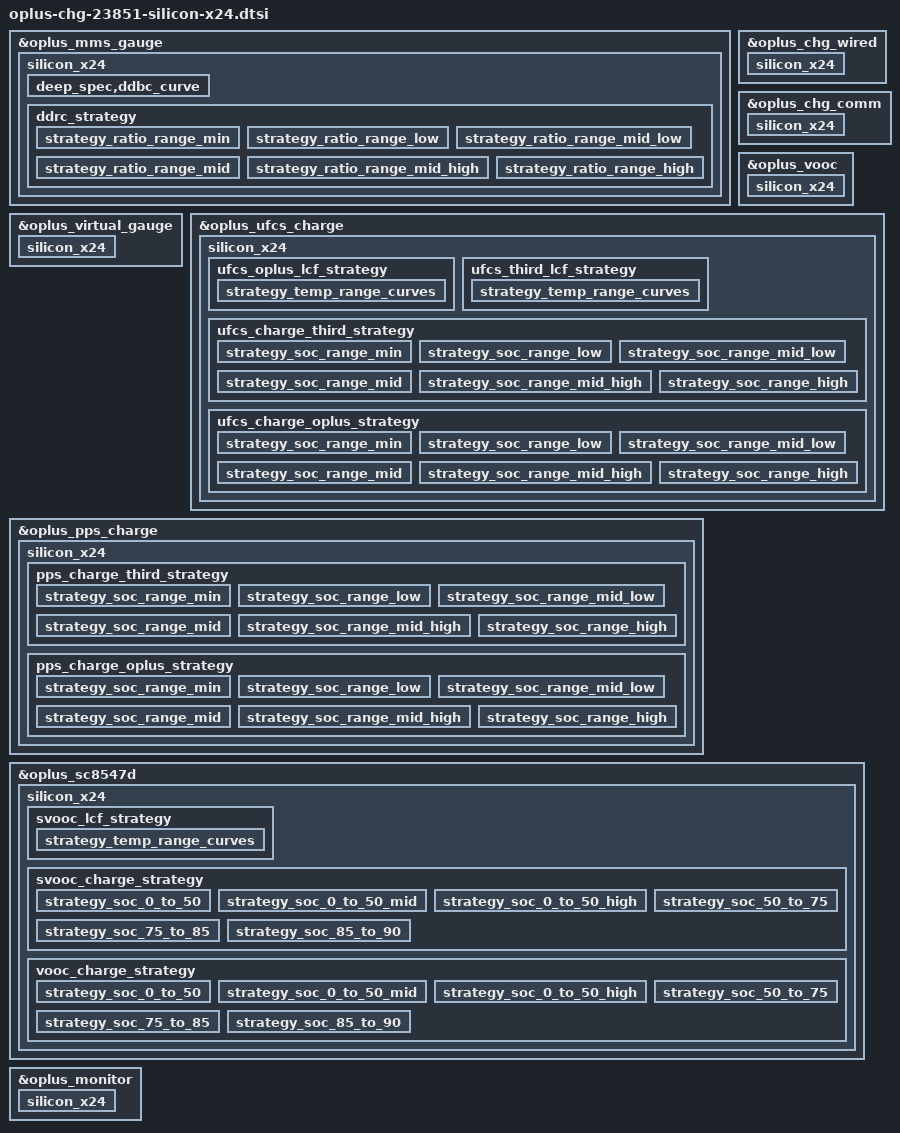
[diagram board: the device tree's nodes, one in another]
&oplus_mms_gauge {
	silicon_x24 {
		oplus,fcl_support;
		oplus,fcl_index = <0>;
		oplus,vb_offset = <30>;
		deep_spec,support;
		deep_spec,uv_thr = <3000>;
		deep_spec,count_thr = <50>;
		deep_spec,vbat_soc = <20>;
		deep_spec,count_step = <0   10 0
					350 12 1
					450 15 2
					530 20 3>;

		deep_spec,term_coeff = <3000 300 0
					3100 450 2
					3200 600 5
					3300 650 7>;
		deep_spec,ddrc_strategy_name = "ddrc_curve";
		deep_spec,volt_step = <20>;
		deep_spec,ddbc_curve {
			oplus,temp_type = <OPLUS_STRATEGY_USE_BATT_TEMP>;
			oplus,temp_range = <(-100) 50 200>;
			deep_spec,ddbc_temp_cold =	<500   3250 5
							 10000 3200 2>;
			deep_spec,ddbc_temp_cool =	<500   3250 5
							 10000 3200 2>;
			deep_spec,ddbc_temp_normal =	<500   3350 5
							 10000 3300 2>;
			deep_spec,ddbc_temp_warm =	<500   3350 5
							 10000 3300 2>;
		};
		ddrc_strategy {
			oplus,temp_type = <OPLUS_STRATEGY_USE_BATT_TEMP>;
			oplus,ratio_range = <20 30 50 70 90>;
			oplus,temp_range = <(-50) 100 350>;
			strategy_ratio_range_min { /* 0 ~ 0.2 */
				strategy_temp_cold =	<0    3000 3000 0
							 15   3000 3000 1
							 1200 3100 3100 2
							 1600 3200 3200 3
							 2000 3300 3300 4>;
				strategy_temp_cool =	<0    3000 3000 0
							 15   3000 3000 1
							 500  3000 3000 2
							 1000 3100 3100 3
							 1500 3200 3200 4
							 2000 3300 3300 5>;
				strategy_temp_normal =	<0    3000 3000 0
							 15   3000 3000 1
							 500  3100 3100 2
							 1000 3200 3200 3
							 1500 3300 3300 4>;
				strategy_temp_warm =	<0    3000 3000 0
							 15   3000 3000 1
							 500  3100 3100 2
							 1000 3200 3200 3
							 1500 3300 3300 4>;
			};
			strategy_ratio_range_low { /* 0.2 ~ 0.3 */
				strategy_temp_cold =	<0    3000 3000 0
							 15   3000 3000 1
							 1000 3100 3100 2
							 1300 3200 3200 3
							 1600 3300 3300 4>;
				strategy_temp_cool =	<0    3000 3000 0
							 15   3000 3000 1
							 400  3000 3000 2
							 800  3100 3100 3
							 1200 3200 3200 4
							 1600 3300 3300 5>;
				strategy_temp_normal =	<0    3000 3000 0
							 15   3000 3000 1
							 400  3100 3100 2
							 800  3200 3200 3
							 1200 3300 3300 4>;
				strategy_temp_warm =	<0    3000 3000 0
							 15   3000 3000 1
							 400  3100 3100 2
							 800  3200 3200 3
							 1200 3300 3300 4>;
			};
			strategy_ratio_range_mid_low { /* 0.3 ~ 0.5 */
				strategy_temp_cold =	<0    3000 3000 0
							 15   3000 3000 1
							 600  3100 3100 2
							 900  3200 3200 3
							 1200 3300 3300 4>;
				strategy_temp_cool =	<0    3000 3000 0
							 15   3000 3000 1
							 300  3000 3000 2
							 600  3100 3100 3
							 900  3200 3200 4
							 1200 3300 3300 5>;
				strategy_temp_normal =	<0    3000 3000 0
							 15   3000 3000 1
							 300  3100 3100 2
							 600  3200 3200 3
							 900  3300 3300 4>;
				strategy_temp_warm =	<0    3000 3000 0
							 15   3000 3000 1
							 300  3100 3100 2
							 600  3200 3200 3
							 900  3300 3300 4>;
			};
			strategy_ratio_range_mid { /* 0.5 ~ 0.7 */
				strategy_temp_cold =	<0    3000 3000 0
							 15   3000 3000 1
							 400  3100 3100 2
							 700  3200 3200 3
							 1000 3300 3300 4>;
				strategy_temp_cool =	<0    3000 3000 0
							 100  3000 3000 1
							 200  3100 3100 2
							 500  3200 3200 3
							 800  3300 3300 4>;
				strategy_temp_normal =	<0    3000 3000 0
							 100  3100 3100 1
							 200  3200 3200 2
							 500  3300 3300 3>;
				strategy_temp_warm =	<0    3000 3000 0
							 100  3100 3100 1
							 200  3200 3200 2
							 500  3300 3300 3>;
			};
			strategy_ratio_range_mid_high { /* 0.7 ~ 0.9 */
				strategy_temp_cold =	<0    3000 3000 0
							 15   3000 3000 1
							 150  3100 3100 2
							 300  3200 3200 3
							 500  3300 3300 4>;
				strategy_temp_cool =	<0    3000 3000 0
							 50   3000 3000 1
							 100  3100 3100 2
							 150  3200 3200 3
							 300  3300 3300 4>;
				strategy_temp_normal =	<0    3000 3000 0
							 50   3100 3100 1
							 100  3200 3200 2
							 150  3300 3300 3>;
				strategy_temp_warm =	<0    3000 3000 0
							 50   3100 3100 1
							 100  3200 3200 2
							 150  3300 3300 3>;
			};
			strategy_ratio_range_high { /* >= 0.9 */
				strategy_temp_cold =	<0    3000 3000 0
							 15   3000 3000 1
							 150  3100 3100 2
							 300  3200 3200 3
							 500  3300 3300 4>;
				strategy_temp_cool =	<0    3000 3000 0
							 50   3000 3000 1
							 100  3100 3100 2
							 150  3200 3200 3
							 300  3300 3300 4>;
				strategy_temp_normal =	<0    3000 3000 0
							 50   3100 3100 1
							 100  3200 3200 2
							 150  3300 3300 3>;
				strategy_temp_warm =	<0    3000 3000 0
							 50   3100 3100 1
							 100  3200 3200 2
							 150  3300 3300 3>;
			};
		};
	};
};

&oplus_virtual_gauge {
	silicon_x24 {
		oplus,gauge_ic = <&oplus_adsp_gauge &oplus_ext_gauge>;
		oplus,gauge_ic_index = <0 1>;
		oplus,gauge_ic_func_group = <&adsp_gauge_groups &bq27541_groups>;
		oplus,batt_capacity_mah = <6415>;
		oplus,ic_type = <OPLUS_CHG_IC_VIRTUAL_GAUGE>;
		oplus,ic_index = <0>;
	};
};

&oplus_chg_wired {
	silicon_x24 {
		oplus,vooc-support;

		oplus_spec,vbatt_pdqc_to_5v_thr = <4500>;
		oplus_spec,vbatt_pdqc_to_9v_thr = <4500>;
		oplus_spec,pd-iclmax-ma = <2000>;
		oplus_spec,qc-iclmax-ma = <2000>;
		oplus_spec,non-standard-ibatmax-ma = <500>;
		oplus_spec,input-power-mw = <
			2500		/* OPLUS_WIRED_CHG_MODE_UNKNOWN */
			2500		/* OPLUS_WIRED_CHG_MODE_SDP */
			7500		/* OPLUS_WIRED_CHG_MODE_CDP */
			10000		/* OPLUS_WIRED_CHG_MODE_DCP */
			10000		/* OPLUS_WIRED_CHG_MODE_VOOC */
			18000		/* OPLUS_WIRED_CHG_MODE_QC */
			18000		/* OPLUS_WIRED_CHG_MODE_PD */
		>;
		oplus_spec,led_on-fccmax-ma = <0 551 2754 4400 4400 4400 4400 1000 0>;
		oplus_spec,fccmax-ma-lv = <
			0 551  2200 2200 2200 2200 2200 2200 0	/* OPLUS_WIRED_CHG_MODE_UNKNOWN */
			0 551  600  600  600  600  600  600  0	/* OPLUS_WIRED_CHG_MODE_SDP */
			0 551  1600 1600 1600 1600 1600 1600 0	/* OPLUS_WIRED_CHG_MODE_CDP */
			0 551  2200 2200 2200 2200 2200 2200 0	/* OPLUS_WIRED_CHG_MODE_DCP */
			0 551  2200 2200 2200 2200 2200 2200 0	/* OPLUS_WIRED_CHG_MODE_VOOC */
			0 551  2754 4400 4400 4400 4400 3366 0	/* OPLUS_WIRED_CHG_MODE_QC */
			0 551  2754 4400 4400 4400 4400 3366 0	/* OPLUS_WIRED_CHG_MODE_PD */
		>;
		oplus_spec,fccmax-ma-hv = <
			0 551  1102 1652 2200 2200 2200 2200 0	/* OPLUS_WIRED_CHG_MODE_UNKNOWN */
			0 551  600  600  600  600  600  600  0	/* OPLUS_WIRED_CHG_MODE_SDP */
			0 551  1102 1600 1600 1600 1600 1600 0	/* OPLUS_WIRED_CHG_MODE_CDP */
			0 551  1102 1652 2200 2200 2200 2200 0	/* OPLUS_WIRED_CHG_MODE_DCP */
			0 551  1102 1652 2200 2200 2200 2200 0	/* OPLUS_WIRED_CHG_MODE_VOOC */
			0 551  1102 1652 2754 4400 4400 3366 0	/* OPLUS_WIRED_CHG_MODE_QC */
			0 551  1102 1652 2754 4400 4400 3366 0	/* OPLUS_WIRED_CHG_MODE_PD */
		>;

		oplus_spec,cool_down_sale_pdqc_vol_mv = <5000>;
		oplus_spec,cool_down_sale_pdqc_curr_ma = <1200>;
		oplus_spec,cool_down_pdqc_vol_mv = <5000 5000 5000 9000 9000>;
		oplus_spec,cool_down_pdqc_curr_ma = <1200 1500 2000 1500 2000>;
		oplus_spec,cool_down_vooc_curr_ma = <1200 1500 2000 2500 3000 3000>;
		oplus_spec,cool_down_normal_curr_ma = <1200 1500 2000>;

		oplus_spec,vbus_ov_thr_mv = <11000 11000>;
		oplus_spec,vbus_uv_thr_mv = <4300 4300>;

		/* first data is strategy used temp type */
		oplus,pd_strategy_name = "cgcl";
		oplus,pd_strategy_data = <OPLUS_STRATEGY_USE_SHELL_TEMP
					    0   420 2000 1 0
					    410 430 1500 2 0
					    420 440 1200 2 1>;
		oplus,qc_strategy_name = "cgcl";
		oplus,qc_strategy_data = <OPLUS_STRATEGY_USE_SHELL_TEMP
					    0   420 2000 1 0
					    410 430 1500 2 0
					    420 440 1200 2 1>;
	};
};

&oplus_chg_comm {
	silicon_x24 {
		oplus_spec,dec_step = <20>;
		oplus_spec,dec-vol-cc-full-thr = <0 400 600 800 1000 1200>;
		oplus_spec,dec-vol-fv-full-mv = <0 20 20 40 40 40>;
		oplus_spec,batt-them-thr = <(-100) 0 50 120 160 350 450 530>;
		oplus_spec,iterm-ma = <316>;
		oplus_spec,removed_bat_decidegc = <390>;
		oplus_spec,fv-mv = <4500 4500 4500 4500 4500 4500 4475 4130 4130>;
		oplus_spec,sw-fv-mv = <4450 4450 4450 4450 4450 4450 4425 4080 4080>;
		oplus_spec,hw-fv-inc-mv = <0 18 18 18 18 18 18 18 0>;
		oplus_spec,sw-over-fv-mv = <4505 4505 4505 4505 4505 4505 4480 4135 4135>;
		oplus_spec,sw-over-fv-dec-mv = <10>;
		oplus_spec,non-standard-sw-fv-mv = <3930>;
		oplus_spec,non-standard-fv-mv = <3980>;
		oplus_spec,non-standard-hw-fv-inc-mv = <18>;
		oplus_spec,non-standard-sw-over-fv-mv = <3985>;
		oplus_spec,non-standard-vbatdet-mv = <3680>;
		oplus_spec,wired-vbatdet-mv = <0 4200 4300 4400 4400 4400 4375 4030 0>;
		oplus_spec,fcc-gear-thr-mv = <4180>;
		oplus_spec,fcc-gear-shake-mv = <500 500 500 400 300 200 200 200 200>;
		oplus_spec,vbatt-ov-thr-mv = <4600>;

		oplus_spec,full_pre_ffc_judge;
		oplus_spec,full-pre-ffc-mv = <4495>;
		oplus_spec,ffc-temp-thr = <120 210 350 440>;
		oplus_spec,wired-ffc-step-max = <2>;
		oplus_spec,wired-ffc-fv-mv = <4630 4630>;

		oplus_spec,wired-ffc-fv-cutoff-mv = <4545 4545 4545
						     4545 4545 4545>;
		oplus_spec,wired-ffc-fcc-ma = <1500 1500 2050
					       1000 1300 1950>;
		oplus_spec,wired-ffc-fcc-cutoff-ma = <1300 1300 1850
						      900  1200 1850>;

		oplus_spec,vbat_uv_thr_mv = <3000>;
		oplus_spec,vbat_charging_uv_thr_mv = <2900>;

		/*If use subboard NTC as battery temp, config it as 20, otherwise 0 */
		oplus_spec,tbatt_power_off_cali_temp = <0>;
		oplus_spec,poweroff_high_batt_temp = <720>;
		oplus_spec,poweroff_emergency_batt_temp = <770>;
		oplus,vooc_show_ui_soc_decimal;
		oplus,ui_soc_decimal_speedmin = <20>;

		oplus,gauge_stuck_jump_support;
		oplus,gauge_stuck_threshold = <15>;
		oplus,gauge_stuck_time = <50>;

		oplus,smooth_switch;
		oplus,reserve_chg_soc = <2>;

		oplus,ui_soc_2_voltage_comp_mv = <30>;
		oplus,chg_shutdown_max_mv = <3000>;

		oplus_spec,drop_soc_2_temp_ladder = <(-50) 0 0 0 0 0 0 0 0 0>;
		oplus_spec,volt_diff_ladder_of_drop_soc_2 = <80 80 0 0 0 0 0 0 0 0>;
		oplus_spec,keep_soc_2_temp_ladder = <(-200) (-50) 0 0 0 0 0 0 0 0>;
		oplus_spec,volt_diff_ladder_of_keep_soc_2 = <10 20 30 0 0 0 0 0 0 0>;
		oplus_spec,back_rm_of_drop_soc_2 = <32>;
		oplus_spec,back_rm_of_drop_soc_1 = <0>;
		oplus_spec,load_current_of_drop_soc_2 = <1000>;
		oplus_spec,load_current_of_drop_soc_1 = <2000>;
		oplus_spec,current_limit_of_drop_soc_2 = <700>;
		oplus_spec,volt_of_fast_drop_soc_1 = <2900>;
		oplus_spec,support_uisoc_low_battery_control;

		oplus_spec,batt_full_time = <300>;
	};
};

&oplus_vooc {
	silicon_x24 {
		oplus,vooc_ic = <&oplus_virtual_vphy>;

		oplus_spec,vooc_soc_range = <50 75 85>;

		oplus,vooc_data_width = <7>;
		oplus,vooc_curr_max = <CP_CURR_LIMIT_7BIT_15_0A>;
		oplus,vooc_project = <VOOC_PROJECT_10V8A_TWO_BAT_SVOOC>;
		oplus,vooc_curr_table_type = <VOOC_CP_CURR_TABLE>;
		oplus,vooc_power_max_w = <80>;
		oplus,voocphy_support = <AP_DUAL_CP_VOOCPHY>;
		oplus,support_fake_vooc_check;
		oplus,smart_chg_bcc_support;
		oplus,subboard_ntc_abnormal_current = <4000>;

		oplus,abnormal_adapter_current = <CP_CURR_LIMIT_7BIT_15_0A CP_CURR_LIMIT_7BIT_15_0A
						CP_CURR_LIMIT_7BIT_10_0A CP_CURR_LIMIT_7BIT_10_0A
						CP_CURR_LIMIT_7BIT_8_0A CP_CURR_LIMIT_7BIT_8_0A
						CP_CURR_LIMIT_7BIT_6_0A CP_CURR_LIMIT_7BIT_6_0A
						CP_CURR_LIMIT_7BIT_4_0A CP_CURR_LIMIT_7BIT_4_0A>;

		oplus,abnormal_over_80w_adapter_current = <CP_CURR_LIMIT_7BIT_15_0A CP_CURR_LIMIT_7BIT_15_0A
						CP_CURR_LIMIT_7BIT_14_0A CP_CURR_LIMIT_7BIT_14_0A
						CP_CURR_LIMIT_7BIT_12_0A CP_CURR_LIMIT_7BIT_12_0A
						CP_CURR_LIMIT_7BIT_10_0A CP_CURR_LIMIT_7BIT_10_0A
						CP_CURR_LIMIT_7BIT_8_0A  CP_CURR_LIMIT_7BIT_8_0A
						CP_CURR_LIMIT_7BIT_6_0A  CP_CURR_LIMIT_7BIT_6_0A
						CP_CURR_LIMIT_7BIT_4_0A CP_CURR_LIMIT_7BIT_4_0A>;

		/* first data is strategy used temp type */
		oplus,general_strategy_name = "cgcl";
		oplus,general_strategy_data = <OPLUS_STRATEGY_USE_SHELL_TEMP
						0   385 CP_CURR_LIMIT_7BIT_15_0A 1 0
						375 405 CP_CURR_LIMIT_7BIT_10_0A 2 0
						395 420 CP_CURR_LIMIT_7BIT_8_0A  3 1
						410 430 CP_CURR_LIMIT_7BIT_7_0A  4 2
						420 440 CP_CURR_LIMIT_7BIT_4_0A  4 3>;

		oplus,bypass_strategy_name = "cgcl";
		oplus,bypass_strategy_data = <OPLUS_STRATEGY_USE_SHELL_TEMP
						0   395 CP_CURR_LIMIT_7BIT_6_0A  1 0
						385 405 CP_CURR_LIMIT_7BIT_4_0A  2 0
						395 415 CP_CURR_LIMIT_7BIT_3_0A  3 1
						405 440 CP_CURR_LIMIT_7BIT_2_0A  3 2>;

		oplus,plc_strategy-data = <&buck_simple_strategy &cp_2t1_simple_strategy &cp_1t1_simple_strategy>;
		oplus,plc_strategy-names = "default", "svooc", "vooc";
	};
};

&oplus_ufcs_charge {
	silicon_x24 {
		oplus,ufcs_ic = <&oplus_virtual_ufcs>;
		oplus,cp_ic = <&oplus_virtual_cp>;
		oplus,dpdm_switch_ic = <&oplus_virtual_dpdm_switch>;

		oplus,impedance_unit = <&oplus_ufcs_impedance_unit>;

		oplus,target_vbus_mv = <11000>;
		oplus,curr_max_ma = <3000>;
		oplus,curr_table_type = <UFCS_CURR_CP_TABLE>;
		oplus,high_imp_compensation_setting_mv = <50>;
		oplus,subboard_ntc_abnormal_current = <4000>;
		oplus,lift_vbus_use_cpvout;

		oplus,ufcs_warm_allow_vol = <4000>;
		oplus,ufcs_warm_allow_soc = <55>;
		oplus,ufcs_strategy_normal_current = <3000>;
		oplus,ufcs_over_high_or_low_current = <3000>;
		oplus,ufcs_timeout_third = <15737>;
		oplus,ufcs_timeout_oplus = <15737>;
		oplus,ufcs_ibat_over_third = <7400>;
		oplus,ufcs_ibat_over_oplus = <7400>;
		oplus,ufcs_full_cool_sw_vbat = <4550>;
		oplus,ufcs_full_normal_sw_vbat = <4550>;
		oplus,ufcs_full_normal_hw_vbat = <4560>;
		oplus,ufcs_full_warm_vbat = <4130>;
		oplus,ufcs_full_cool_sw_vbat_third = <4500>;
		oplus,ufcs_full_normal_sw_vbat_third= <4500>;
		oplus,ufcs_full_normal_hw_vbat_third = <4510>;
		oplus,ufcs_strategy_batt_high_temp = <405 420 430 395 410 425>;
		oplus,ufcs_strategy_high_current = <3000 2500 2000 3000 3000 2500>;
		oplus,ufcs_little_cool_high_temp = <210>;
		oplus,curve_strategy_name = "pps_ufcs_curve_v2";
		oplus,ufcs_charge_strategy_soc = <0 20 35 55 75 85 95>;
		oplus,ufcs_charge_strategy_temp = <0 50 120 160 350 440 510>;
		oplus_spec,ufcs_low_temp = <0>;
		oplus_spec,ufcs_high_temp = <500>;
		oplus_spec,ufcs_low_soc = <0>;
		oplus_spec,ufcs_high_soc = <95>;

		oplus,plc_strategy-data = <&oplus_ufcs_step_strategy &cp_2t1_simple_strategy>;
		oplus,plc_strategy-names = "default", "third";

		ufcs_oplus_lcf_strategy {
			oplus,temp_type = <OPLUS_STRATEGY_USE_SHELL_TEMP>;
			oplus,temp_range = <0 50 120 160 210 380 440>;

			strategy_temp_range_curves {
				strategy_temp_range_t0 =	<700  4550 0
								 675  4540 0
								 650  4530 0
								 625  4520 0
								 600  4510 1>;
				strategy_temp_range_t1 =	<780  4550 0
								 745  4545 0
								 710  4530 0
								 675  4520 0
								 640  4510 1>;
				strategy_temp_range_t2 =	<800  4550 0
								 755  4545 0
								 710  4530 0
								 665  4520 0
								 620  4510 1>;
				strategy_temp_range_t3 =	<950  4550 0
								 900  4545 0
								 800  4530 0
								 700  4520 0
								 550  4510 1>;
				strategy_temp_range_t4 =	<1250 4550 0
								 1200 4545 0
								 1100 4530 0
								 1000 4520 0
								 850  4510 1>;
				strategy_temp_range_t5 =	<1900 4550 0
								 1850 4545 0
								 1750 4530 0
								 1650 4520 0
								 1500 4510 1>;
			};
		};

		ufcs_third_lcf_strategy {
			oplus,temp_type = <OPLUS_STRATEGY_USE_SHELL_TEMP>;
			oplus,temp_range = <0 50 120 160 210 380 440>;

			strategy_temp_range_curves {
				strategy_temp_range_t0 =	<700  4550 0
								 675  4540 0
								 650  4530 0
								 625  4520 0
								 600  4510 1>;
				strategy_temp_range_t1 =	<780  4550 0
								 745  4545 0
								 710  4530 0
								 675  4520 0
								 640  4510 1>;
				strategy_temp_range_t2 =	<800  4550 0
								 755  4545 0
								 710  4530 0
								 665  4520 0
								 620  4510 1>;
				strategy_temp_range_t3 =	<950  4550 0
								 900  4545 0
								 800  4530 0
								 700  4520 0
								 550  4510 1>;
				strategy_temp_range_t4 =	<1250 4550 0
								 1200 4545 0
								 1100 4530 0
								 1000 4520 0
								 850  4510 1>;
				strategy_temp_range_t5 =	<1900 4550 0
								 1850 4545 0
								 1750 4530 0
								 1650 4520 0
								 1500 4510 1>;
			};
		};

		ufcs_charge_third_strategy {
			oplus,temp_type = <OPLUS_STRATEGY_USE_SHELL_TEMP>;
			oplus,soc_range = <0 20 35 55 75 85 95>;
			oplus,temp_range = <0 50 120 160 210 350 440 510>;

			strategy_soc_range_min { /* 0 ~ 20 */
				strategy_temp_little_cold =	<11000 4140 1450 0 0
								 11000 4150 1000 1 0>;
				strategy_temp_cool =		<11000 4150 2350 0 0
								 11000 4150 2000 0 0
								 11000 4150 1500 0 0
								 11000 4490 1450 0 0
								 11000 4500 1000 1 0>;
				strategy_temp_little_cool =	<11000 4150 2900 0 0
								 11000 4150 2500 0 0
								 11000 4260 2350 0 0
								 11000 4260 2000 0 0
								 11000 4260 1500 0 0
								 11000 4490 1450 0 0
								 11000 4500 1000 1 0>;
				strategy_temp_little_cool_high =<11000 4490 3000 0 0
								 11000 4490 2900 0 0
								 11000 4490 2500 0 0
								 11000 4490 2000 0 0
								 11000 4490 1500 0 0
								 11000 4500 1000 1 0>;
				strategy_temp_normal_low =	<11000 4480 3000 0 0
								 11000 4490 2750 0 0
								 11000 4490 2500 0 0
								 11000 4490 2000 0 0
								 11000 4490 1500 0 0
								 11000 4500 1000 1 0>;
				strategy_temp_normal_high =	<11000 4465 3000 0 0
								 11000 4465 2750 0 0
								 11000 4465 2500 0 0
								 11000 4465 2000 0 0
								 11000 4465 1500 0 0
								 11000 4475 1000 1 0>;
				strategy_temp_warm =		<11000 4120 1650 0 0
								 11000 4120 1500 0 0
								 11000 4130 1000 1 0>;
			};
			strategy_soc_range_low { /* 21 ~ 35 */
				strategy_temp_little_cold =	<11000 4140 1450 0 0
								 11000 4150 1000 1 0>;
				strategy_temp_cool =		<11000 4150 2350 0 0
								 11000 4150 2000 0 0
								 11000 4150 1500 0 0
								 11000 4490 1450 0 0
								 11000 4500 1000 1 0>;
				strategy_temp_little_cool =	<11000 4150 2900 0 0
								 11000 4150 2500 0 0
								 11000 4260 2350 0 0
								 11000 4260 2000 0 0
								 11000 4260 1500 0 0
								 11000 4490 1450 0 0
								 11000 4500 1000 1 0>;
				strategy_temp_little_cool_high =<11000 4490 3000 0 0
								 11000 4490 2900 0 0
								 11000 4490 2500 0 0
								 11000 4490 2000 0 0
								 11000 4490 1500 0 0
								 11000 4500 1000 1 0>;
				strategy_temp_normal_low =	<11000 4480 3000 0 0
								 11000 4490 2750 0 0
								 11000 4490 2500 0 0
								 11000 4490 2000 0 0
								 11000 4490 1500 0 0
								 11000 4500 1000 1 0>;
				strategy_temp_normal_high =	<11000 4465 3000 0 0
								 11000 4465 2750 0 0
								 11000 4465 2500 0 0
								 11000 4465 2000 0 0
								 11000 4465 1500 0 0
								 11000 4475 1000 1 0>;
				strategy_temp_warm =		<11000 4120 1650 0 0
								 11000 4120 1500 0 0
								 11000 4130 1000 1 0>;
			};
			strategy_soc_range_mid_low { /* 36 ~ 55 */
				strategy_temp_little_cold =	<11000 4140 1450 0 0
								 11000 4150 1000 1 0>;
				strategy_temp_cool =		<11000 4150 2350 0 0
								 11000 4150 2000 0 0
								 11000 4150 1500 0 0
								 11000 4490 1450 0 0
								 11000 4500 1000 1 0>;
				strategy_temp_little_cool =	<11000 4150 2900 0 0
								 11000 4150 2500 0 0
								 11000 4260 2350 0 0
								 11000 4260 2000 0 0
								 11000 4260 1500 0 0
								 11000 4490 1450 0 0
								 11000 4500 1000 1 0>;
				strategy_temp_little_cool_high =<11000 4490 3000 0 0
								 11000 4490 2900 0 0
								 11000 4490 2500 0 0
								 11000 4490 2000 0 0
								 11000 4490 1500 0 0
								 11000 4500 1000 1 0>;
				strategy_temp_normal_low =	<11000 4480 3000 0 0
								 11000 4490 2750 0 0
								 11000 4490 2500 0 0
								 11000 4490 2000 0 0
								 11000 4490 1500 0 0
								 11000 4500 1000 1 0>;
				strategy_temp_normal_high =	<11000 4465 3000 0 0
								 11000 4465 2750 0 0
								 11000 4465 2500 0 0
								 11000 4465 2000 0 0
								 11000 4465 1500 0 0
								 11000 4475 1000 1 0>;
				strategy_temp_warm =		<11000 4120 1650 0 0
								 11000 4120 1500 0 0
								 11000 4130 1000 1 0>;
			};
			strategy_soc_range_mid { /* 56 ~ 75*/
				strategy_temp_little_cold =	<11000 4140 1450 0 0
								 11000 4150 1000 1 0>;
				strategy_temp_cool =		<11000 4150 1500 0 0
								 11000 4490 1450 0 0
								 11000 4500 1000 1 0>;
				strategy_temp_little_cool =	<11000 4260 2000 0 0
								 11000 4260 1500 0 0
								 11000 4490 1450 0 0
								 11000 4500 1000 1 0>;
				strategy_temp_little_cool_high =<11000 4490 2000 0 0
								 11000 4490 1500 0 0
								 11000 4500 1000 1 0>;
				strategy_temp_normal_low =	<11000 4490 2000 0 0
								 11000 4490 1500 0 0
								 11000 4500 1000 1 0>;
				strategy_temp_normal_high =	<11000 4465 2500 0 0
								 11000 4465 2000 0 0
								 11000 4465 1500 0 0
								 11000 4475 1000 1 0>;
				strategy_temp_warm =		<11000 4120 1650 0 0
								 11000 4120 1500 0 0
								 11000 4130 1000 1 0>;
			};
			strategy_soc_range_mid_high { /* 76 ~ 85 */
				strategy_temp_little_cold =	<11000 4150 1000 1 0>;
				strategy_temp_cool =		<11000 4500 1000 1 0>;
				strategy_temp_little_cool =	<11000 4260 1500 0 0
								 11000 4490 1450 0 0
								 11000 4500 1000 1 0>;
				strategy_temp_little_cool_high =<11000 4490 1500 0 0
								 11000 4500 1000 1 0>;
				strategy_temp_normal_low =	<11000 4490 1500 0 0
								 11000 4500 1000 1 0>;
				strategy_temp_normal_high =	<11000 4465 1500 0 0
								 11000 4475 1000 1 0>;
				strategy_temp_warm =		<11000 4120 1650 0 0
								 11000 4120 1500 0 0
								 11000 4130 1000 1 0>;
			};
			strategy_soc_range_high { /* 86 ~ 95 */
				strategy_temp_little_cold =	<11000 4150 1000 1 0>;
				strategy_temp_cool =		<11000 4500 1000 1 0>;
				strategy_temp_little_cool =	<11000 4500 1000 1 0>;
				strategy_temp_little_cool_high =<11000 4500 1000 1 0>;
				strategy_temp_normal_low =	<11000 4500 1000 1 0>;
				strategy_temp_normal_high =	<11000 4475 1000 1 0>;
				strategy_temp_warm =		<11000 4120 1650 0 0
								 11000 4120 1500 0 0
								 11000 4130 1000 1 0>;
			};
		};

		ufcs_charge_oplus_strategy {
			oplus,temp_type = <OPLUS_STRATEGY_USE_SHELL_TEMP>;
			oplus,soc_range = <0 20 35 55 75 85 95>;
			oplus,temp_range = <0 50 120 160 210 350 440 510>;

			strategy_soc_range_min { /* 0 ~ 20 */
				strategy_temp_little_cold =	<11000 4140 1450 0 0
								 11000 4150 1000 1 0>;
				strategy_temp_cool =		<11000 4150 2350 0 0
								 11000 4150 2000 0 0
								 11000 4150 1500 0 0
								 11000 4500 1450 0 0
								 11000 4510 1000 1 0>;
				strategy_temp_little_cool =	<11000 4150 2900 0 0
								 11000 4150 2500 0 0
								 11000 4260 2350 0 0
								 11000 4260 2000 0 0
								 11000 4260 1500 0 0
								 11000 4540 1450 0 0
								 11000 4550 1000 1 0>;
				strategy_temp_little_cool_high =<11000 4500 3000 0 0
								 11000 4540 2900 0 0
								 11000 4540 2500 0 0
								 11000 4540 2000 0 0
								 11000 4540 1500 0 0
								 11000 4550 1000 1 0>;
				strategy_temp_normal_low =	<11000 4480 3000 0 0
								 11000 4540 2750 0 0
								 11000 4540 2500 0 0
								 11000 4540 2000 0 0
								 11000 4540 1500 0 0
								 11000 4550 1000 1 0>;
				strategy_temp_normal_high =	<11000 4480 3000 0 0
								 11000 4540 2750 0 0
								 11000 4540 2500 0 0
								 11000 4540 2000 0 0
								 11000 4540 1500 0 0
								 11000 4550 1000 1 0>;
				strategy_temp_warm =		<11000 4120 1650 0 0
								 11000 4120 1500 0 0
								 11000 4130 1000 1 0>;
			};
			strategy_soc_range_low { /* 21 ~ 35 */
				strategy_temp_little_cold =	<11000 4140 1450 0 0
								 11000 4150 1000 1 0>;
				strategy_temp_cool =		<11000 4150 2350 0 0
								 11000 4150 2000 0 0
								 11000 4150 1500 0 0
								 11000 4500 1450 0 0
								 11000 4510 1000 1 0>;
				strategy_temp_little_cool =	<11000 4150 2900 0 0
								 11000 4150 2500 0 0
								 11000 4260 2350 0 0
								 11000 4260 2000 0 0
								 11000 4260 1500 0 0
								 11000 4540 1450 0 0
								 11000 4550 1000 1 0>;
				strategy_temp_little_cool_high =<11000 4500 3000 0 0
								 11000 4540 2900 0 0
								 11000 4540 2500 0 0
								 11000 4540 2000 0 0
								 11000 4540 1500 0 0
								 11000 4550 1000 1 0>;
				strategy_temp_normal_low =	<11000 4480 3000 0 0
								 11000 4540 2750 0 0
								 11000 4540 2500 0 0
								 11000 4540 2000 0 0
								 11000 4540 1500 0 0
								 11000 4550 1000 1 0>;
				strategy_temp_normal_high =	<11000 4480 3000 0 0
								 11000 4540 2750 0 0
								 11000 4540 2500 0 0
								 11000 4540 2000 0 0
								 11000 4540 1500 0 0
								 11000 4550 1000 1 0>;
				strategy_temp_warm =		<11000 4120 1650 0 0
								 11000 4120 1500 0 0
								 11000 4130 1000 1 0>;
			};
			strategy_soc_range_mid_low { /* 36 ~ 55 */
				strategy_temp_little_cold =	<11000 4140 1450 0 0
								 11000 4150 1000 1 0>;
				strategy_temp_cool =		<11000 4150 2350 0 0
								 11000 4150 2000 0 0
								 11000 4150 1500 0 0
								 11000 4500 1450 0 0
								 11000 4510 1000 1 0>;
				strategy_temp_little_cool =	<11000 4150 2900 0 0
								 11000 4150 2500 0 0
								 11000 4260 2350 0 0
								 11000 4260 2000 0 0
								 11000 4260 1500 0 0
								 11000 4540 1450 0 0
								 11000 4550 1000 1 0>;
				strategy_temp_little_cool_high =<11000 4500 3000 0 0
								 11000 4540 2900 0 0
								 11000 4540 2500 0 0
								 11000 4540 2000 0 0
								 11000 4540 1500 0 0
								 11000 4550 1000 1 0>;
				strategy_temp_normal_low =	<11000 4480 3000 0 0
								 11000 4540 2750 0 0
								 11000 4540 2500 0 0
								 11000 4540 2000 0 0
								 11000 4540 1500 0 0
								 11000 4550 1000 1 0>;
				strategy_temp_normal_high =	<11000 4480 3000 0 0
								 11000 4540 2750 0 0
								 11000 4540 2500 0 0
								 11000 4540 2000 0 0
								 11000 4540 1500 0 0
								 11000 4550 1000 1 0>;
				strategy_temp_warm =		<11000 4120 1650 0 0
								 11000 4120 1500 0 0
								 11000 4130 1000 1 0>;
			};
			strategy_soc_range_mid { /* 56 ~ 75 */
				strategy_temp_little_cold =	<11000 4140 1450 0 0
								 11000 4150 1000 1 0>;
				strategy_temp_cool =		<11000 4150 1500 0 0
								 11000 4500 1450 0 0
								 11000 4510 1000 1 0>;
				strategy_temp_little_cool =	<11000 4260 2000 0 0
								 11000 4260 1500 0 0
								 11000 4540 1450 0 0
								 11000 4550 1000 1 0>;
				strategy_temp_little_cool_high =<11000 4540 2000 0 0
								 11000 4540 1500 0 0
								 11000 4550 1000 1 0>;
				strategy_temp_normal_low =	<11000 4540 2500 0 0
								 11000 4540 2000 0 0
								 11000 4540 1500 0 0
								 11000 4550 1000 1 0>;
				strategy_temp_normal_high =	<11000 4480 3000 0 0
								 11000 4540 2750 0 0
								 11000 4540 2500 0 0
								 11000 4540 2000 0 0
								 11000 4540 1500 0 0
								 11000 4550 1000 1 0>;
				strategy_temp_warm =		<11000 4120 1650 0 0
								 11000 4120 1500 0 0
								 11000 4130 1000 1 0>;
			};
			strategy_soc_range_mid_high { /* 76 ~ 85 */
				strategy_temp_little_cold =	<11000 4150 1000 1 0>;
				strategy_temp_cool =		<11000 4510 1000 1 0>;
				strategy_temp_little_cool =	<11000 4260 1500 0 0
								 11000 4540 1450 0 0
								 11000 4550 1000 1 0>;
				strategy_temp_little_cool_high =<11000 4540 1500 0 0
								 11000 4550 1000 1 0>;
				strategy_temp_normal_low =	<11000 4540 1500 0 0
								 11000 4550 1000 1 0>;
				strategy_temp_normal_high =	<11000 4540 2000 0 0
								 11000 4540 1500 0 0
								 11000 4550 1000 1 0>;
				strategy_temp_warm =		<11000 4120 1650 0 0
								 11000 4120 1500 0 0
								 11000 4130 1000 1 0>;
			};
			strategy_soc_range_high { /* 86 ~ 95 */
				strategy_temp_little_cold =	<11000 4150 1000 1 0>;
				strategy_temp_cool =		<11000 4510 1000 1 0>;
				strategy_temp_little_cool =	<11000 4550 1000 1 0>;
				strategy_temp_little_cool_high =<11000 4550 1000 1 0>;
				strategy_temp_normal_low =	<11000 4550 1000 1 0>;
				strategy_temp_normal_high =	<11000 4550 1000 1 0>;
				strategy_temp_warm =		<11000 4120 1650 0 0
								 11000 4120 1500 0 0
								 11000 4130 1000 1 0>;
			};
		};
	};
};

&oplus_pps_charge {
	silicon_x24 {
		oplus,pps_ic = <&oplus_virtual_pps>;
		oplus,cp_ic = <&oplus_virtual_cp>;
		oplus,dpdm_switch_ic = <&oplus_virtual_dpdm_switch>;

		oplus,target_vbus_mv = <11000>;
		oplus,curr_max_ma = <5000>;
		oplus,lift_vbus_use_cpvout;
		oplus,process_close_cp_item;

		oplus,pps_warm_allow_vol = <4000>;
		oplus,pps_warm_allow_soc = <55>;
		oplus,pps_strategy_normal_current = <5000>;
		oplus,pps_over_high_or_low_current = <5000>;
		oplus,pps_timeout_third = <15737>;
		oplus,pps_timeout_oplus = <15737>;
		oplus,pps_ibat_over_third = <55 11400
					     33 7400>;
		oplus,pps_ibat_over_oplus = <55 11400
					     33 7400>;
		oplus,pps_full_cool_sw_vbat = <4500>;
		oplus,pps_full_normal_sw_vbat = <4500>;
		oplus,pps_full_normal_hw_vbat = <4510>;
		oplus,pps_full_warm_vbat = <4130>;
		oplus,pps_full_cool_sw_vbat_third = <4500>;
		oplus,pps_full_normal_sw_vbat_third= <4500>;
		oplus,pps_full_normal_hw_vbat_third = <4510>;
		oplus,pps_strategy_batt_high_temp = <410 430 435 400 425 430>;
		oplus,pps_strategy_high_current = <5000 3000 2000 5000 5000 3000>;
		oplus,pps_little_cool_high_temp = <210>;
		oplus,curve_strategy_name = "pps_ufcs_curve_v2";
		oplus,pps_charge_strategy_soc = <0 20 35 55 75 85 95>;
		oplus,pps_charge_strategy_temp = <0 50 120 160 350 440 510>;

		oplus,plc_strategy-data = <&cp_2t1_simple_strategy>;
		oplus,plc_strategy-names = "default";

		pps_charge_third_strategy {
			oplus,temp_type = <OPLUS_STRATEGY_USE_SHELL_TEMP>;
			oplus,soc_range = <0 20 35 55 75 85 95>;
			oplus,temp_range = <0 50 120 160 210 350 440 510>;

			strategy_soc_range_min { /* 0 ~ 20 */
				strategy_temp_little_cold =	<11000 4140 1450 0 0
								 11000 4150 1000 1 0>;
				strategy_temp_cool =		<11000 4150 2350 0 0
								 11000 4150 2000 0 0
								 11000 4150 1500 0 0
								 11000 4490 1450 0 0
								 11000 4500 1000 1 0>;
				strategy_temp_little_cool =	<11000 4150 2900 0 0
								 11000 4150 2500 0 0
								 11000 4260 2350 0 0
								 11000 4260 2000 0 0
								 11000 4260 1500 0 0
								 11000 4490 1450 0 0
								 11000 4500 1000 1 0>;
				strategy_temp_little_cool_high =<11000 4170 5000 0 600
								 11000 4170 4500 0 0
								 11000 4260 4350 0 0
								 11000 4260 4000 0 0
								 11000 4490 3500 0 0
								 11000 4490 3000 0 0
								 11000 4490 2900 0 0
								 11000 4490 2500 0 0
								 11000 4490 2000 0 0
								 11000 4490 1500 0 0
								 11000 4500 1000 1 0>;
				strategy_temp_normal_low =	<11000 4190 5000 0 600
								 11000 4250 4950 0 0
								 11000 4250 4000 0 0
								 11000 4410 3850 0 0
								 11000 4480 3550 0 0
								 11000 4480 3500 0 0
								 11000 4480 3000 0 0
								 11000 4490 2750 0 0
								 11000 4490 2500 0 0
								 11000 4490 2000 0 0
								 11000 4490 1500 0 0
								 11000 4500 1000 1 0>;
				strategy_temp_normal_high =	<11000 4190 5000 0 600
								 11000 4250 4950 0 0
								 11000 4250 4000 0 0
								 11000 4410 3850 0 0
								 11000 4465 3550 0 0
								 11000 4465 3500 0 0
								 11000 4465 3000 0 0
								 11000 4465 2750 0 0
								 11000 4465 2500 0 0
								 11000 4465 2000 0 0
								 11000 4465 1500 0 0
								 11000 4475 1000 1 0>;
				strategy_temp_warm =		<11000 4120 1650 0 0
								 11000 4120 1500 0 0
								 11000 4130 1000 1 0>;
			};
			strategy_soc_range_low { /* 21 ~ 35 */
				strategy_temp_little_cold =	<11000 4140 1450 0 0
								 11000 4150 1000 1 0>;
				strategy_temp_cool =		<11000 4150 2350 0 0
								 11000 4150 2000 0 0
								 11000 4150 1500 0 0
								 11000 4490 1450 0 0
								 11000 4500 1000 1 0>;
				strategy_temp_little_cool =	<11000 4150 2900 0 0
								 11000 4150 2500 0 0
								 11000 4260 2350 0 0
								 11000 4260 2000 0 0
								 11000 4260 1500 0 0
								 11000 4490 1450 0 0
								 11000 4500 1000 1 0>;
				strategy_temp_little_cool_high =<11000 4170 5000 0 600
								 11000 4170 4500 0 0
								 11000 4260 4350 0 0
								 11000 4260 4000 0 0
								 11000 4490 3500 0 0
								 11000 4490 3000 0 0
								 11000 4490 2900 0 0
								 11000 4490 2500 0 0
								 11000 4490 2000 0 0
								 11000 4490 1500 0 0
								 11000 4500 1000 1 0>;
				strategy_temp_normal_low =	<11000 4190 5000 0 600
								 11000 4250 4950 0 0
								 11000 4250 4000 0 0
								 11000 4410 3850 0 0
								 11000 4480 3550 0 0
								 11000 4480 3500 0 0
								 11000 4480 3000 0 0
								 11000 4490 2750 0 0
								 11000 4490 2500 0 0
								 11000 4490 2000 0 0
								 11000 4490 1500 0 0
								 11000 4500 1000 1 0>;
				strategy_temp_normal_high =	<11000 4190 5000 0 600
								 11000 4250 4950 0 0
								 11000 4250 4000 0 0
								 11000 4410 3850 0 0
								 11000 4465 3550 0 0
								 11000 4465 3500 0 0
								 11000 4465 3000 0 0
								 11000 4465 2750 0 0
								 11000 4465 2500 0 0
								 11000 4465 2000 0 0
								 11000 4465 1500 0 0
								 11000 4475 1000 1 0>;
				strategy_temp_warm =		<11000 4120 1650 0 0
								 11000 4120 1500 0 0
								 11000 4130 1000 1 0>;
			};
			strategy_soc_range_mid_low { /* 36 ~ 55 */
				strategy_temp_little_cold =	<11000 4140 1450 0 0
								 11000 4150 1000 1 0>;
				strategy_temp_cool =		<11000 4150 2350 0 0
								 11000 4150 2000 0 0
								 11000 4150 1500 0 0
								 11000 4490 1450 0 0
								 11000 4500 1000 1 0>;
				strategy_temp_little_cool =	<11000 4150 2900 0 0
								 11000 4150 2500 0 0
								 11000 4260 2350 0 0
								 11000 4260 2000 0 0
								 11000 4260 1500 0 0
								 11000 4490 1450 0 0
								 11000 4500 1000 1 0>;
				strategy_temp_little_cool_high =<11000 4490 3000 0 0
								 11000 4490 2900 0 0
								 11000 4490 2500 0 0
								 11000 4490 2000 0 0
								 11000 4490 1500 0 0
								 11000 4500 1000 1 0>;
				strategy_temp_normal_low =	<11000 4190 5000 0 600
								 11000 4250 4950 0 0
								 11000 4250 4000 0 0
								 11000 4410 3850 0 0
								 11000 4480 3550 0 0
								 11000 4480 3500 0 0
								 11000 4480 3000 0 0
								 11000 4490 2750 0 0
								 11000 4490 2500 0 0
								 11000 4490 2000 0 0
								 11000 4490 1500 0 0
								 11000 4500 1000 1 0>;
				strategy_temp_normal_high =	<11000 4190 5000 0 600
								 11000 4250 4950 0 0
								 11000 4250 4000 0 0
								 11000 4410 3850 0 0
								 11000 4465 3550 0 0
								 11000 4465 3500 0 0
								 11000 4465 3000 0 0
								 11000 4465 2750 0 0
								 11000 4465 2500 0 0
								 11000 4465 2000 0 0
								 11000 4465 1500 0 0
								 11000 4475 1000 1 0>;
				strategy_temp_warm =		<11000 4120 1650 0 0
								 11000 4120 1500 0 0
								 11000 4130 1000 1 0>;
			};
			strategy_soc_range_mid { /* 56 ~ 75*/
				strategy_temp_little_cold =	<11000 4140 1450 0 0
								 11000 4150 1000 1 0>;
				strategy_temp_cool =		<11000 4150 1500 0 0
								 11000 4490 1450 0 0
								 11000 4500 1000 1 0>;
				strategy_temp_little_cool =	<11000 4260 2000 0 0
								 11000 4260 1500 0 0
								 11000 4490 1450 0 0
								 11000 4500 1000 1 0>;
				strategy_temp_little_cool_high =<11000 4490 2000 0 0
								 11000 4490 1500 0 0
								 11000 4500 1000 1 0>;
				strategy_temp_normal_low =	<11000 4490 2000 0 0
								 11000 4490 1500 0 0
								 11000 4500 1000 1 0>;
				strategy_temp_normal_high =	<11000 4465 2500 0 0
								 11000 4465 2000 0 0
								 11000 4465 1500 0 0
								 11000 4475 1000 1 0>;
				strategy_temp_warm =		<11000 4120 1650 0 0
								 11000 4120 1500 0 0
								 11000 4130 1000 1 0>;
			};
			strategy_soc_range_mid_high { /* 76 ~ 85 */
				strategy_temp_little_cold =	<11000 4150 1000 1 0>;
				strategy_temp_cool =		<11000 4500 1000 1 0>;
				strategy_temp_little_cool =	<11000 4260 1500 0 0
								 11000 4490 1450 0 0
								 11000 4500 1000 1 0>;
				strategy_temp_little_cool_high =<11000 4490 1500 0 0
								 11000 4500 1000 1 0>;
				strategy_temp_normal_low =	<11000 4490 1500 0 0
								 11000 4500 1000 1 0>;
				strategy_temp_normal_high =	<11000 4465 1500 0 0
								 11000 4475 1000 1 0>;
				strategy_temp_warm =		<11000 4120 1650 0 0
								 11000 4120 1500 0 0
								 11000 4130 1000 1 0>;
			};
			strategy_soc_range_high { /* 86 ~ 95 */
				strategy_temp_little_cold =	<11000 4150 1000 1 0>;
				strategy_temp_cool =		<11000 4500 1000 1 0>;
				strategy_temp_little_cool =	<11000 4500 1000 1 0>;
				strategy_temp_little_cool_high =<11000 4500 1000 1 0>;
				strategy_temp_normal_low =	<11000 4500 1000 1 0>;
				strategy_temp_normal_high =	<11000 4475 1000 1 0>;
				strategy_temp_warm =		<11000 4120 1650 0 0
								 11000 4120 1500 0 0
								 11000 4130 1000 1 0>;
			};
		};

		pps_charge_oplus_strategy {
			oplus,temp_type = <OPLUS_STRATEGY_USE_SHELL_TEMP>;
			oplus,soc_range = <0 20 35 55 75 85 95>;
			oplus,temp_range = <0 50 120 160 210 350 440 510>;

			strategy_soc_range_min { /* 0 ~ 20 */
				strategy_temp_little_cold =	<11000 4140 1450 0 0
								 11000 4150 1000 1 0>;
				strategy_temp_cool =		<11000 4150 2350 0 0
								 11000 4150 2000 0 0
								 11000 4150 1500 0 0
								 11000 4490 1450 0 0
								 11000 4500 1000 1 0>;
				strategy_temp_little_cool =	<11000 4150 2900 0 0
								 11000 4150 2500 0 0
								 11000 4260 2350 0 0
								 11000 4260 2000 0 0
								 11000 4260 1500 0 0
								 11000 4490 1450 0 0
								 11000 4500 1000 1 0>;
				strategy_temp_little_cool_high =<11000 4170 5000 0 600
								 11000 4170 4500 0 0
								 11000 4260 4350 0 0
								 11000 4260 4000 0 0
								 11000 4490 3500 0 0
								 11000 4490 3000 0 0
								 11000 4490 2900 0 0
								 11000 4490 2500 0 0
								 11000 4490 2000 0 0
								 11000 4490 1500 0 0
								 11000 4500 1000 1 0>;
				strategy_temp_normal_low =	<11000 4190 5000 0 600
								 11000 4250 4950 0 0
								 11000 4250 4000 0 0
								 11000 4410 3850 0 0
								 11000 4480 3550 0 0
								 11000 4480 3500 0 0
								 11000 4480 3000 0 0
								 11000 4490 2750 0 0
								 11000 4490 2500 0 0
								 11000 4490 2000 0 0
								 11000 4490 1500 0 0
								 11000 4500 1000 1 0>;
				strategy_temp_normal_high =	<11000 4190 5000 0 600
								 11000 4250 4950 0 0
								 11000 4250 4000 0 0
								 11000 4410 3850 0 0
								 11000 4465 3550 0 0
								 11000 4465 3500 0 0
								 11000 4465 3000 0 0
								 11000 4465 2750 0 0
								 11000 4465 2500 0 0
								 11000 4465 2000 0 0
								 11000 4465 1500 0 0
								 11000 4475 1000 1 0>;
				strategy_temp_warm =		<11000 4120 1650 0 0
								 11000 4120 1500 0 0
								 11000 4130 1000 1 0>;
			};
			strategy_soc_range_low { /* 21 ~ 35 */
				strategy_temp_little_cold =	<11000 4140 1450 0 0
								 11000 4150 1000 1 0>;
				strategy_temp_cool =		<11000 4150 2350 0 0
								 11000 4150 2000 0 0
								 11000 4150 1500 0 0
								 11000 4490 1450 0 0
								 11000 4500 1000 1 0>;
				strategy_temp_little_cool =	<11000 4150 2900 0 0
								 11000 4150 2500 0 0
								 11000 4260 2350 0 0
								 11000 4260 2000 0 0
								 11000 4260 1500 0 0
								 11000 4490 1450 0 0
								 11000 4500 1000 1 0>;
				strategy_temp_little_cool_high =<11000 4170 5000 0 600
								 11000 4170 4500 0 0
								 11000 4260 4350 0 0
								 11000 4260 4000 0 0
								 11000 4490 3500 0 0
								 11000 4490 3000 0 0
								 11000 4490 2900 0 0
								 11000 4490 2500 0 0
								 11000 4490 2000 0 0
								 11000 4490 1500 0 0
								 11000 4500 1000 1 0>;
				strategy_temp_normal_low =	<11000 4190 5000 0 600
								 11000 4250 4950 0 0
								 11000 4250 4000 0 0
								 11000 4410 3850 0 0
								 11000 4480 3550 0 0
								 11000 4480 3500 0 0
								 11000 4480 3000 0 0
								 11000 4490 2750 0 0
								 11000 4490 2500 0 0
								 11000 4490 2000 0 0
								 11000 4490 1500 0 0
								 11000 4500 1000 1 0>;
				strategy_temp_normal_high =	<11000 4190 5000 0 600
								 11000 4250 4950 0 0
								 11000 4250 4000 0 0
								 11000 4410 3850 0 0
								 11000 4465 3550 0 0
								 11000 4465 3500 0 0
								 11000 4465 3000 0 0
								 11000 4465 2750 0 0
								 11000 4465 2500 0 0
								 11000 4465 2000 0 0
								 11000 4465 1500 0 0
								 11000 4475 1000 1 0>;
				strategy_temp_warm =		<11000 4120 1650 0 0
								 11000 4120 1500 0 0
								 11000 4130 1000 1 0>;
			};
			strategy_soc_range_mid_low { /* 36 ~ 55 */
				strategy_temp_little_cold =	<11000 4140 1450 0 0
								 11000 4150 1000 1 0>;
				strategy_temp_cool =		<11000 4150 2350 0 0
								 11000 4150 2000 0 0
								 11000 4150 1500 0 0
								 11000 4490 1450 0 0
								 11000 4500 1000 1 0>;
				strategy_temp_little_cool =	<11000 4150 2900 0 0
								 11000 4150 2500 0 0
								 11000 4260 2350 0 0
								 11000 4260 2000 0 0
								 11000 4260 1500 0 0
								 11000 4490 1450 0 0
								 11000 4500 1000 1 0>;
				strategy_temp_little_cool_high =<11000 4490 3000 0 0
								 11000 4490 2900 0 0
								 11000 4490 2500 0 0
								 11000 4490 2000 0 0
								 11000 4490 1500 0 0
								 11000 4500 1000 1 0>;
				strategy_temp_normal_low =	<11000 4190 5000 0 600
								 11000 4250 4950 0 0
								 11000 4250 4000 0 0
								 11000 4410 3850 0 0
								 11000 4480 3550 0 0
								 11000 4480 3500 0 0
								 11000 4480 3000 0 0
								 11000 4490 2750 0 0
								 11000 4490 2500 0 0
								 11000 4490 2000 0 0
								 11000 4490 1500 0 0
								 11000 4500 1000 1 0>;
				strategy_temp_normal_high =	<11000 4190 5000 0 600
								 11000 4250 4950 0 0
								 11000 4250 4000 0 0
								 11000 4410 3850 0 0
								 11000 4465 3550 0 0
								 11000 4465 3500 0 0
								 11000 4465 3000 0 0
								 11000 4465 2750 0 0
								 11000 4465 2500 0 0
								 11000 4465 2000 0 0
								 11000 4465 1500 0 0
								 11000 4475 1000 1 0>;
				strategy_temp_warm =		<11000 4120 1650 0 0
								 11000 4120 1500 0 0
								 11000 4130 1000 1 0>;
			};
			strategy_soc_range_mid { /* 56 ~ 75*/
				strategy_temp_little_cold =	<11000 4140 1450 0 0
								 11000 4150 1000 1 0>;
				strategy_temp_cool =		<11000 4150 1500 0 0
								 11000 4490 1450 0 0
								 11000 4500 1000 1 0>;
				strategy_temp_little_cool =	<11000 4260 2000 0 0
								 11000 4260 1500 0 0
								 11000 4490 1450 0 0
								 11000 4500 1000 1 0>;
				strategy_temp_little_cool_high =<11000 4490 2000 0 0
								 11000 4490 1500 0 0
								 11000 4500 1000 1 0>;
				strategy_temp_normal_low =	<11000 4490 2000 0 0
								 11000 4490 1500 0 0
								 11000 4500 1000 1 0>;
				strategy_temp_normal_high =	<11000 4465 2500 0 0
								 11000 4465 2000 0 0
								 11000 4465 1500 0 0
								 11000 4475 1000 1 0>;
				strategy_temp_warm =		<11000 4120 1650 0 0
								 11000 4120 1500 0 0
								 11000 4130 1000 1 0>;
			};
			strategy_soc_range_mid_high { /* 76 ~ 85 */
				strategy_temp_little_cold =	<11000 4150 1000 1 0>;
				strategy_temp_cool =		<11000 4500 1000 1 0>;
				strategy_temp_little_cool =	<11000 4260 1500 0 0
								 11000 4490 1450 0 0
								 11000 4500 1000 1 0>;
				strategy_temp_little_cool_high =<11000 4490 1500 0 0
								 11000 4500 1000 1 0>;
				strategy_temp_normal_low =	<11000 4490 1500 0 0
								 11000 4500 1000 1 0>;
				strategy_temp_normal_high =	<11000 4465 1500 0 0
								 11000 4475 1000 1 0>;
				strategy_temp_warm =		<11000 4120 1650 0 0
								 11000 4120 1500 0 0
								 11000 4130 1000 1 0>;
			};
			strategy_soc_range_high { /* 86 ~ 95 */
				strategy_temp_little_cold =	<11000 4150 1000 1 0>;
				strategy_temp_cool =		<11000 4500 1000 1 0>;
				strategy_temp_little_cool =	<11000 4500 1000 1 0>;
				strategy_temp_little_cool_high =<11000 4500 1000 1 0>;
				strategy_temp_normal_low =	<11000 4500 1000 1 0>;
				strategy_temp_normal_high =	<11000 4475 1000 1 0>;
				strategy_temp_warm =		<11000 4120 1650 0 0
								 11000 4120 1500 0 0
								 11000 4130 1000 1 0>;
			};
		};
	};
};

&oplus_sc8547d {
	silicon_x24 {
		oplus,use_vooc_phy;
		oplus,use_ufcs_phy;
		oplus,vac_support;
		oplus,always_otg_en;

		oplus_spec,irq_gpio = <&tlmm 8 0x00>;

		pinctrl-names = "charging_inter_active", "charging_inter_sleep";
		pinctrl-0 = <&charging_inter_active>;
		pinctrl-1 = <&charging_inter_sleep>;

		oplus,ic_type = <OPLUS_CHG_IC_VPHY>;
		oplus,ic_index = <0>;
		oplus,vooc-version = <VOOC_VERSION_5_0>;

		oplus_spec,vooc_bad_volt = <3450 3400 3350 3300>;
		oplus_spec,vooc_bad_volt_suspend = <3450 3400 3350 3300>;
		oplus_spec,vooc_bad_volt_check_head_mask = /bits/ 8 <0x3>; /* VOOC 2.0/VOOC3.0 */
		oplus_spec,ap_control_allow;

		oplus_spec,external_gauge_support;
		oplus_spec,voocphy_current_default = <73>;

		oplus_spec,vooc_little_cold_full_voltage = <4150>;
		oplus_spec,vooc_cool_full_voltage = <4510>;
		oplus_spec,vooc_warm_full_voltage = <4130>;
		oplus_spec,vooc_1time_full_voltage = <4560>;
		oplus_spec,vooc_ntime_full_voltage = <4550>;
		oplus_spec,full_voltage = < /* vol_1time vol_ntime */
					4160 4150 /* 0 ~ 5 */
					4520 4510 /* 5 ~ 12 */
					4560 4550 /* 12 ~ 16 */
					4560 4550 /* 16 ~ 20 */
					4560 4550 /* 20 ~ 35 */
					4560 4550 /* 35 ~ 44 */
					4140 4130 /* 44 ~ 51 */
					>;

		ocp_reg = <0xe>;
		ovp_reg = <0x36>;
		oplus_spec,voocphy_dual_cp_support;
		oplus_spec,slave_cp_enable_thr = <1400>;
		oplus_spec,slave_cp_disable_thr_high = <1100>;
		oplus_spec,impedance_calculation_newmethod;
		oplus_spec,svooc_circuit_r_l = <0xa>;
		oplus_spec,svooc_circuit_r_h = <0x1>;

		oplus_spec,vooc_multistep_initial_batt_temp = <1000>;
		oplus_spec,vooc_little_cool_temp = <160>;
		oplus_spec,vooc_little_cool_high_temp = <210>;
		oplus_spec,vooc_cool_temp = <120>;
		oplus_spec,vooc_little_cold_temp = <50>;
		oplus_spec,vooc_normal_low_temp = <350>;
		oplus_spec,vooc_normal_to_little_cool_current = <100>;
		oplus_spec,vooc_over_high_temp = <510>;
		oplus_spec,vooc_low_temp = <0>;
		oplus_spec,vooc_high_temp = <500>;
		oplus_spec,vooc_low_soc = <0>;
		oplus_spec,vooc_high_soc = <95>;
		oplus_spec,vooc_normal_high_temp = <440>;
		oplus_spec,vooc_warm_vol_thr = <4000>;
		oplus_spec,vooc_warm_soc_thr = <55>;

		oplus_spec,fastchg_timeout_time_init = <157370>;
		oplus_spec,voocphy_ibat_over_current = <16000>;
		oplus_spec,voocphy_cp_max_ibus = <4500>;

		oplus_spec,voocphy_req_freq = <1920000 2956800 2956800 3302400>;
		oplus_spec,voocphy_freq_mincore = <1920000>;
		oplus_spec,voocphy_freq_midcore = <2956800>;
		oplus_spec,voocphy_freq_maxcore = <2956800>;
		oplus_spec,voocphy_current_change_timeout = <100>;
		oplus_spec,copycat_vooc_support;

		oplus_spec,soc_range = <0 20 35 55 75 85 95>;

		svooc_batt_sys_curve = <1 0 0 1 0 0 1	// 7300mA
					0 0 0 0 0 0 1	// 3414mV
					0 0 1 1 0 1 0	// 2600mA
					1 1 1 1 1 1 0	// 4664mV
					0 0 0 1 0 1 1	// 1100mA
					1 1 1 1 1 1 0>;	// 4664mV

		vooc_batt_sys_curve =  <0 1 1 1 1 0 0	// 6000mA
					0 0 0 0 0 0 1	// 3414mV
					0 0 1 1 0 1 0	// 2600mA
					1 1 1 1 1 1 0	// 4664mV
					0 0 0 1 0 1 1	// 1100mA
					1 1 1 1 1 1 0>;	// 4664mV

		svooc_lcf_strategy {
			oplus,temp_type = <OPLUS_STRATEGY_USE_SHELL_TEMP>;
			oplus,temp_range = <0 50 120 160 210 380 440>;

			strategy_temp_range_curves {
				strategy_temp_range_t0 =	<700  4550 0
								 675  4540 0
								 650  4530 0
								 625  4520 0
								 600  4510 1>;
				strategy_temp_range_t1 =	<780  4550 0
								 745  4545 0
								 710  4530 0
								 675  4520 0
								 640  4510 1>;
				strategy_temp_range_t2 =	<800  4550 0
								 755  4545 0
								 710  4530 0
								 665  4520 0
								 620  4510 1>;
				strategy_temp_range_t3 =	<950  4550 0
								 900  4545 0
								 800  4530 0
								 700  4520 0
								 550  4510 1>;
				strategy_temp_range_t4 =	<1250 4550 0
								 1200 4545 0
								 1100 4530 0
								 1000 4520 0
								 850  4510 1>;
				strategy_temp_range_t5 =	<1900 4550 0
								 1850 4545 0
								 1750 4530 0
								 1650 4520 0
								 1500 4510 1>;
			};
		};

		svooc_charge_strategy {
			strategy_soc_0_to_50 { /* 0 ~ 20 */
				strategy_temp_little_cold =	<4140 14 0 0 0
								 4150 10 1 0 0>;
				strategy_temp_cool =		<4150 23 0 0 0
								 4150 20 0 0 0
								 4150 15 0 0 0
								 4500 14 0 0 0
								 4510 10 1 0 0>;
				strategy_temp_little_cool =	<4150 29 0 0 0
								 4150 25 0 0 0
								 4260 23 0 0 0
								 4260 20 0 0 0
								 4260 15 0 0 0
								 4540 14 0 0 0
								 4550 10 1 0 0>;
				strategy_temp_little_cool_high =<4170 58 0 1200 0
								 4170 55 0 1200 0
								 4170 50 0 1200 0
								 4260 43 0 0 0
								 4260 40 0 0 0
								 4500 35 0 0 0
								 4500 30 0 0 0
								 4540 29 0 0 0
								 4540 25 0 0 0
								 4540 20 0 0 0
								 4540 15 0 0 0
								 4550 10 1 0 0>;
				strategy_temp_normal_low =	<4150 73 0 60 0
								 4190 61 0 480 0
								 4190 50 0 1200 0
								 4250 49 0 0 0
								 4250 40 0 0 0
								 4410 38 0 0 0
								 4480 35 0 0 0
								 4480 30 0 0 0
								 4540 27 0 0 0
								 4540 25 0 0 0
								 4540 22 0 0 0
								 4540 20 0 0 0
								 4540 17 0 0 0
								 4540 15 0 0 0
								 4540 12 0 0 0
								 4550 10 1 0 0>;
				strategy_temp_normal_high =	<4150 73 0 60 0
								 4190 61 0 480 0
								 4190 50 0 1200 0
								 4250 49 0 0 0
								 4250 40 0 0 0
								 4410 38 0 0 0
								 4480 35 0 0 0
								 4480 30 0 0 0
								 4540 27 0 0 0
								 4540 25 0 0 0
								 4540 22 0 0 0
								 4540 20 0 0 0
								 4540 17 0 0 0
								 4540 15 0 0 0
								 4540 12 0 0 0
								 4550 10 1 0 0>;
				strategy_temp_warm =		<4120 16 0 0 0
								 4120 15 0 0 0
								 4130 10 1 0 0>;
			};

			strategy_soc_0_to_50_mid { /* 21 ~ 35 */
				strategy_temp_little_cold =	<4140 14 0 0 0
								 4150 10 1 0 0>;
				strategy_temp_cool =		<4150 23 0 0 0
								 4150 20 0 0 0
								 4150 15 0 0 0
								 4500 14 0 0 0
								 4510 10 1 0 0>;
				strategy_temp_little_cool =	<4150 29 0 0 0
								 4150 25 0 0 0
								 4260 23 0 0 0
								 4260 20 0 0 0
								 4260 15 0 0 0
								 4540 14 0 0 0
								 4550 10 1 0 0>;
				strategy_temp_little_cool_high =<4170 58 0 1200 0
								 4170 55 0 1200 0
								 4170 50 0 1200 0
								 4260 43 0 0 0
								 4260 40 0 0 0
								 4500 35 0 0 0
								 4500 30 0 0 0
								 4540 29 0 0 0
								 4540 25 0 0 0
								 4540 20 0 0 0
								 4540 15 0 0 0
								 4550 10 1 0 0>;
				strategy_temp_normal_low =	<4150 73 0 60 0
								 4190 61 0 480 0
								 4190 50 0 1200 0
								 4250 49 0 0 0
								 4250 40 0 0 0
								 4410 38 0 0 0
								 4480 35 0 0 0
								 4480 30 0 0 0
								 4540 27 0 0 0
								 4540 25 0 0 0
								 4540 22 0 0 0
								 4540 20 0 0 0
								 4540 17 0 0 0
								 4540 15 0 0 0
								 4540 12 0 0 0
								 4550 10 1 0 0>;
				strategy_temp_normal_high =	<4150 73 0 60 0
								 4190 61 0 480 0
								 4190 50 0 1200 0
								 4250 49 0 0 0
								 4250 40 0 0 0
								 4410 38 0 0 0
								 4480 35 0 0 0
								 4480 30 0 0 0
								 4540 27 0 0 0
								 4540 25 0 0 0
								 4540 22 0 0 0
								 4540 20 0 0 0
								 4540 17 0 0 0
								 4540 15 0 0 0
								 4540 12 0 0 0
								 4550 10 1 0 0>;
				strategy_temp_warm =		<4120 16 0 0 0
								 4120 15 0 0 0
								 4130 10 1 0 0>;
			};

			strategy_soc_0_to_50_high { /* 36 ~ 55 */
				strategy_temp_little_cold =	<4140 14 0 0 0
								 4150 10 1 0 0>;
				strategy_temp_cool =		<4150 23 0 0 0
								 4150 20 0 0 0
								 4150 15 0 0 0
								 4500 14 0 0 0
								 4510 10 1 0 0>;
				strategy_temp_little_cool =	<4150 29 0 0 0
								 4150 25 0 0 0
								 4260 23 0 0 0
								 4260 20 0 0 0
								 4260 15 0 0 0
								 4540 14 0 0 0
								 4550 10 1 0 0>;
				strategy_temp_little_cool_high =<4260 40 0 0 0
								 4500 35 0 0 0
								 4500 30 0 0 0
								 4540 29 0 0 0
								 4540 25 0 0 0
								 4540 20 0 0 0
								 4540 15 0 0 0
								 4550 10 1 0 0>;
				strategy_temp_normal_low =	<4150 73 0 60 0
								 4190 61 0 480 0
								 4190 50 0 1200 0
								 4250 49 0 0 0
								 4250 40 0 0 0
								 4410 38 0 0 0
								 4480 35 0 0 0
								 4480 30 0 0 0
								 4540 27 0 0 0
								 4540 25 0 0 0
								 4540 22 0 0 0
								 4540 20 0 0 0
								 4540 17 0 0 0
								 4540 15 0 0 0
								 4540 12 0 0 0
								 4550 10 1 0 0>;
				strategy_temp_normal_high =	<4150 73 0 60 0
								 4190 61 0 480 0
								 4190 50 0 1200 0
								 4250 49 0 0 0
								 4250 40 0 0 0
								 4410 38 0 0 0
								 4480 35 0 0 0
								 4480 30 0 0 0
								 4540 27 0 0 0
								 4540 25 0 0 0
								 4540 22 0 0 0
								 4540 20 0 0 0
								 4540 17 0 0 0
								 4540 15 0 0 0
								 4540 12 0 0 0
								 4550 10 1 0 0>;
				strategy_temp_warm =		<4120 16 0 0 0
								 4120 15 0 0 0
								 4130 10 1 0 0>;
			};

			strategy_soc_50_to_75 { /* 56 ~ 75 */
				strategy_temp_little_cold =	<4140 14 0 0 0
								 4150 10 1 0 0>;
				strategy_temp_cool =		<4150 15 0 0 0
								 4500 14 0 0 0
								 4510 10 1 0 0>;
				strategy_temp_little_cool =	<4260 20 0 0 0
								 4260 15 0 0 0
								 4540 14 0 0 0
								 4550 10 1 0 0>;
				strategy_temp_little_cool_high =<4540 20 0 0 0
								 4540 15 0 0 0
								 4550 10 1 0 0>;
				strategy_temp_normal_low =	<4540 25 0 0 0
								 4540 22 0 0 0
								 4540 20 0 0 0
								 4540 17 0 0 0
								 4540 15 0 0 0
								 4540 12 0 0 0
								 4550 10 1 0 0>;
				strategy_temp_normal_high =	<4480 30 0 0 0
								 4540 27 0 0 0
								 4540 25 0 0 0
								 4540 22 0 0 0
								 4540 20 0 0 0
								 4540 17 0 0 0
								 4540 15 0 0 0
								 4540 12 0 0 0
								 4550 10 1 0 0>;
				strategy_temp_warm =		<4120 16 0 0 0
								 4120 15 0 0 0
								 4130 10 1 0 0>;
			};

			strategy_soc_75_to_85 { /* 76 ~ 85 */
				strategy_temp_little_cold =	<4150 10 1 0 0>;
				strategy_temp_cool =		<4510 10 1 0 0>;
				strategy_temp_little_cool =	<4260 15 0 0 0
								 4540 14 0 0 0
								 4550 10 1 0 0>;
				strategy_temp_little_cool_high =<4540 15 0 0 0
								 4550 10 1 0 0>;
				strategy_temp_normal_low =	<4540 15 0 0 0
								 4540 12 0 0 0
								 4550 10 1 0 0>;
				strategy_temp_normal_high =	<4540 20 0 0 0
								 4540 17 0 0 0
								 4540 15 0 0 0
								 4540 12 0 0 0
								 4550 10 1 0 0>;
				strategy_temp_warm =		<4120 16 0 0 0
								 4120 15 0 0 0
								 4130 10 1 0 0>;
			};

			strategy_soc_85_to_90 { /* 86 ~ 95 */
				strategy_temp_little_cold =	<4150 10 1 0 0>;
				strategy_temp_cool =		<4510 10 1 0 0>;
				strategy_temp_little_cool =	<4550 10 1 0 0>;
				strategy_temp_little_cool_high =<4550 10 1 0 0>;
				strategy_temp_normal_low =	<4550 10 1 0 0>;
				strategy_temp_normal_high =	<4550 10 1 0 0>;
				strategy_temp_warm =		<4120 16 0 0 0
								 4120 15 0 0 0
								 4130 10 1 0 0>;
			};
		};

		vooc_charge_strategy {
			strategy_soc_0_to_50 { /* 0 ~ 20 */
				strategy_temp_little_cold =	<4140 28 0 0 0
								 4150 20 1 0 0>;
				strategy_temp_cool =		<4150 46 0 0 0
								 4150 40 0 0 0
								 4150 30 0 0 0
								 4500 28 0 0 0
								 4510 20 1 0 0>;
				strategy_temp_little_cool =	<4150 58 0 0 0
								 4150 50 0 0 0
								 4260 46 0 0 0
								 4260 40 0 0 0
								 4260 30 0 0 0
								 4540 28 0 0 0
								 4550 20 1 0 0>;
				strategy_temp_little_cool_high =<4500 60 0 0 0
								 4540 58 0 0 0
								 4540 50 0 0 0
								 4540 40 0 0 0
								 4540 30 0 0 0
								 4550 20 1 0 0>;
				strategy_temp_normal_low =	<4480 60 0 0 0
								 4540 54 0 0 0
								 4540 50 0 0 0
								 4540 40 0 0 0
								 4540 30 0 0 0
								 4550 20 1 0 0>;
				strategy_temp_normal_high =	<4480 60 0 0 0
								 4540 54 0 0 0
								 4540 50 0 0 0
								 4540 40 0 0 0
								 4540 30 0 0 0
								 4550 20 1 0 0>;
				strategy_temp_warm =		<4120 32 0 0 0
								 4120 30 0 0 0
								 4130 20 1 0 0>;
			};

			strategy_soc_0_to_50_mid { /* 21 ~ 35 */
				strategy_temp_little_cold =	<4140 28 0 0 0
								 4150 20 1 0 0>;
				strategy_temp_cool =		<4150 46 0 0 0
								 4150 40 0 0 0
								 4150 30 0 0 0
								 4500 28 0 0 0
								 4510 20 1 0 0>;
				strategy_temp_little_cool =	<4150 58 0 0 0
								 4150 50 0 0 0
								 4260 46 0 0 0
								 4260 40 0 0 0
								 4260 30 0 0 0
								 4540 28 0 0 0
								 4550 20 1 0 0>;
				strategy_temp_little_cool_high =<4500 60 0 0 0
								 4540 58 0 0 0
								 4540 50 0 0 0
								 4540 40 0 0 0
								 4540 30 0 0 0
								 4550 20 1 0 0>;
				strategy_temp_normal_low =	<4480 60 0 0 0
								 4540 54 0 0 0
								 4540 50 0 0 0
								 4540 40 0 0 0
								 4540 30 0 0 0
								 4550 20 1 0 0>;
				strategy_temp_normal_high =	<4480 60 0 0 0
								 4540 54 0 0 0
								 4540 50 0 0 0
								 4540 40 0 0 0
								 4540 30 0 0 0
								 4550 20 1 0 0>;
				strategy_temp_warm =		<4120 32 0 0 0
								 4120 30 0 0 0
								 4130 20 1 0 0>;
			};

			strategy_soc_0_to_50_high { /* 36 ~ 55 */
				strategy_temp_little_cold =	<4140 28 0 0 0
								 4150 20 1 0 0>;
				strategy_temp_cool =		<4150 46 0 0 0
								 4150 40 0 0 0
								 4150 30 0 0 0
								 4500 28 0 0 0
								 4510 20 1 0 0>;
				strategy_temp_little_cool =	<4150 58 0 0 0
								 4150 50 0 0 0
								 4260 46 0 0 0
								 4260 40 0 0 0
								 4260 30 0 0 0
								 4540 28 0 0 0
								 4550 20 1 0 0>;
				strategy_temp_little_cool_high =<4500 60 0 0 0
								 4540 58 0 0 0
								 4540 50 0 0 0
								 4540 40 0 0 0
								 4540 30 0 0 0
								 4550 20 1 0 0>;
				strategy_temp_normal_low =	<4480 60 0 0 0
								 4540 54 0 0 0
								 4540 50 0 0 0
								 4540 40 0 0 0
								 4540 30 0 0 0
								 4550 20 1 0 0>;
				strategy_temp_normal_high =	<4480 60 0 0 0
								 4540 54 0 0 0
								 4540 50 0 0 0
								 4540 40 0 0 0
								 4540 30 0 0 0
								 4550 20 1 0 0>;
				strategy_temp_warm =		<4120 32 0 0 0
								 4120 30 0 0 0
								 4130 20 1 0 0>;
			};

			strategy_soc_50_to_75 { /* 56 ~ 75 */
				strategy_temp_little_cold =	<4140 28 0 0 0
								 4150 20 1 0 0>;
				strategy_temp_cool =		<4150 30 0 0 0
								 4500 28 0 0 0
								 4510 20 1 0 0>;
				strategy_temp_little_cool =	<4260 40 0 0 0
								 4260 30 0 0 0
								 4540 28 0 0 0
								 4550 20 1 0 0>;
				strategy_temp_little_cool_high =<4540 40 0 0 0
								 4540 30 0 0 0
								 4550 20 1 0 0>;
				strategy_temp_normal_low =	<4540 50 0 0 0
								 4540 40 0 0 0
								 4540 30 0 0 0
								 4550 20 1 0 0>;
				strategy_temp_normal_high =	<4480 60 0 0 0
								 4540 54 0 0 0
								 4540 50 0 0 0
								 4540 40 0 0 0
								 4540 30 0 0 0
								 4550 20 1 0 0>;
				strategy_temp_warm =		<4120 32 0 0 0
								 4120 30 0 0 0
								 4130 20 1 0 0>;
			};

			strategy_soc_75_to_85 { /* 76 ~ 85 */
				strategy_temp_little_cold =	<4150 20 1 0 0>;
				strategy_temp_cool =		<4510 20 1 0 0>;
				strategy_temp_little_cool =	<4260 30 0 0 0
								 4540 28 0 0 0
								 4550 20 1 0 0>;
				strategy_temp_little_cool_high =<4540 30 0 0 0
								 4550 20 1 0 0>;
				strategy_temp_normal_low =	<4540 30 0 0 0
								 4550 20 1 0 0>;
				strategy_temp_normal_high =	<4540 40 0 0 0
								 4540 30 0 0 0
								 4550 20 1 0 0>;
				strategy_temp_warm =		<4120 32 0 0 0
								 4120 30 0 0 0
								 4130 20 1 0 0>;
			};

			strategy_soc_85_to_90 { /* 86 ~ 95 */
				strategy_temp_little_cold =	<4150 20 1 0 0>;
				strategy_temp_cool =		<4510 20 1 0 0>;
				strategy_temp_little_cool =	<4550 20 1 0 0>;
				strategy_temp_little_cool_high =<4550 20 1 0 0>;
				strategy_temp_normal_low =	<4550 20 1 0 0>;
				strategy_temp_normal_high =	<4550 20 1 0 0>;
				strategy_temp_warm =		<4120 32 0 0 0
								 4120 30 0 0 0
								 4130 20 1 0 0>;
			};
		};
	};
};

&oplus_monitor {
	silicon_x24 {
		track,fast_chg_break_t_thd = <2500>;
		track,general_chg_break_t_thd = <300>;
		track,voocphy_type = <TRACK_AP_DUAL_CP_VOOCPHY>;
		track,wired_max_power = <80000>;
		track,wired_fast_chg_scheme = <TRACK_WIRED_SCHEME_SINGLE_60W_67W>;
		track,track_ver = <TRACK_VER_4_0>;

		track,gauge_status_ctrl;
		track,nominal_qmax1 = <6579>;
		track,nominal_fcc1 = <5828>;
		track,external_gauge_num = <1>;

		track,gauge_max_cell_vol = <4600>;
		track,gauge_max_charge_curr = <13000>;
		track,gauge_max_dischg_curr = <6000>;
		track,gauge_min_cell_temp = <30>;
		track,gauge_max_cell_temp = <70>;
		track,gauge_lifetime_support;
	};
};
